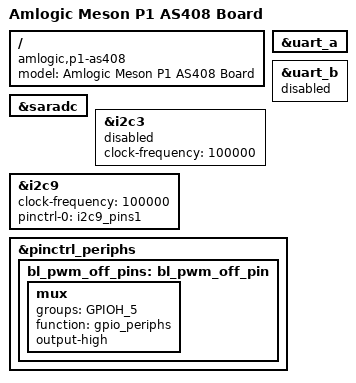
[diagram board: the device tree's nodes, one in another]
/*
 * Copyright (c) 2016 Endless Computers, Inc.
 * Author: Carlo Caione <carlo@endlessm.com>
 *
 * This file is dual-licensed: you can use it either under the terms
 * of the GPL or the X11 license, at your option. Note that this dual
 * licensing only applies to this file, and not this project as a
 * whole.
 *
 *  a) This library is free software; you can redistribute it and/or
 *     modify it under the terms of the GNU General Public License as
 *     published by the Free Software Foundation; either version 2 of the
 *     License, or (at your option) any later version.
 *
 *     This library is distributed in the hope that it will be useful,
 *     but WITHOUT ANY WARRANTY; without even the implied warranty of
 *     MERCHANTABILITY or FITNESS FOR A PARTICULAR PURPOSE.  See the
 *     GNU General Public License for more details.
 *
 * Or, alternatively,
 *
 *  b) Permission is hereby granted, free of charge, to any person
 *     obtaining a copy of this software and associated documentation
 *     files (the "Software"), to deal in the Software without
 *     restriction, including without limitation the rights to use,
 *     copy, modify, merge, publish, distribute, sublicense, and/or
 *     sell copies of the Software, and to permit persons to whom the
 *     Software is furnished to do so, subject to the following
 *     conditions:
 *
 *     The above copyright notice and this permission notice shall be
 *     included in all copies or substantial portions of the Software.
 *
 *     THE SOFTWARE IS PROVIDED "AS IS", WITHOUT WARRANTY OF ANY KIND,
 *     EXPRESS OR IMPLIED, INCLUDING BUT NOT LIMITED TO THE WARRANTIES
 *     OF MERCHANTABILITY, FITNESS FOR A PARTICULAR PURPOSE AND
 *     NONINFRINGEMENT. IN NO EVENT SHALL THE AUTHORS OR COPYRIGHT
 *     HOLDERS BE LIABLE FOR ANY CLAIM, DAMAGES OR OTHER LIABILITY,
 *     WHETHER IN AN ACTION OF CONTRACT, TORT OR OTHERWISE, ARISING
 *     FROM, OUT OF OR IN CONNECTION WITH THE SOFTWARE OR THE USE OR
 *     OTHER DEALINGS IN THE SOFTWARE.
 */

/dts-v1/;

#include "meson-p1-as408.dtsi"
#include "meson-p1_skt-panel.dtsi"

/ {
	compatible = "amlogic,p1-as408", "amlogic,p1-txxx", "amlogic,meson-p1";
	model = "Amlogic Meson P1 AS408 Board";
};

/* This UART is brought out to the DB9 connector */
&uart_a {
	status = "okay";
};

&uart_b {
	status = "disabled";
};

&saradc {
	status = "okay";
};

/* demo for i2c user */
&i2c3 {
	status= "disabled";
	clock-frequency = <100000>;
	/* pinctrl-names = "default";*/
	/* pinctrl-0 = <&i2c3_master_pins2>;*/
};

/* pmic71888/pmic2657 */
&i2c9 {
	status= "okay";
	clock-frequency = <100000>;
	pinctrl-names = "default";
	pinctrl-0 = <&i2c9_pins1>;
};

&pinctrl_periphs {
	bl_pwm_off_pins:bl_pwm_off_pin {
		mux {
			groups = "GPIOH_5";
			function = "gpio_periphs";
			output-high;
		};
	};
}; /* end of pinctrl_periphs */
